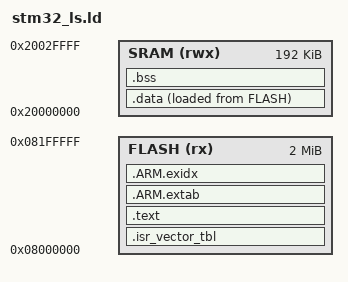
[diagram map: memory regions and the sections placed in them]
ENTRY(Reset_Handler)

MEMORY
{
    FLASH (rx)  : ORIGIN = 0x08000000, LENGTH = 2048K
    SRAM  (rwx) : ORIGIN = 0x20000000, LENGTH = 192K
}

_estack = ORIGIN(SRAM) + LENGTH(SRAM);
_max_heap_size  = 0x200;
_max_stack_size = 0x400;

SECTIONS
{
    .isr_vector_tbl : 
    {
 	KEEP(*(.isr_vector_tbl))
    } > FLASH

    .text :
    {
        . = ALIGN(512);
        KEEP(*(.isr_vector_tbl))
        . = ALIGN(4);
        *(.text .text.*)
        *(.rodata .rodata.*)
        . = ALIGN(4);
    } > FLASH

    .ARM.extab :
    {
        *(.ARM.extab* .gnu.linkonce.armextab.*)
    } > FLASH

    .ARM.exidx :
    {
        *(.ARM.exidx* .gnu.linkonce.armexidx.*)
    } > FLASH

    .data :
    {
        . = ALIGN(4);
        _sdata = .;
        *(.data .data.*)
        . = ALIGN(4);
        _edata = .;
    } > SRAM AT > FLASH

    _etext = LOADADDR(.data);

    .bss (NOLOAD) :
    {
        . = ALIGN(4);
        _sbss = .;
        *(.bss .bss.*)
        *(COMMON)
        . = ALIGN(4);
        _ebss = .;
    } > SRAM
}
